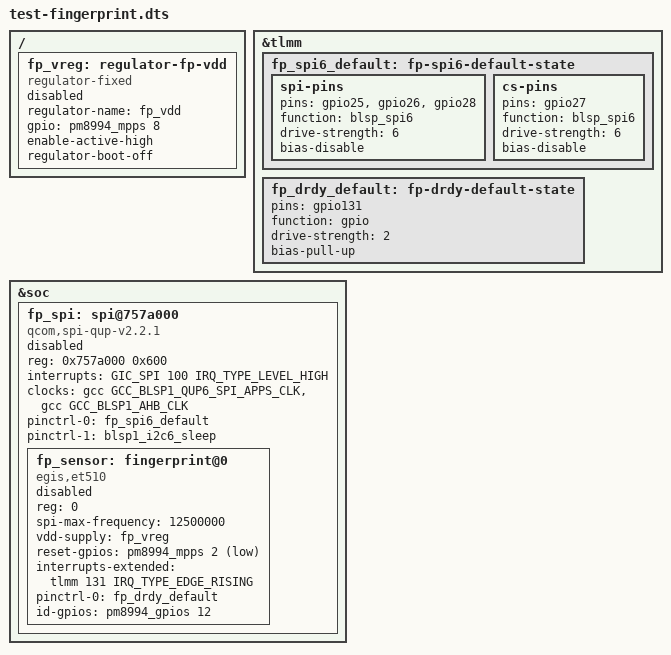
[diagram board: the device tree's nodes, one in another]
// SPDX-License-Identifier: BSD-3-Clause
/*
 * TEST ONLY - fingerprint SPI bring-up for the Galaxy Tab S3.
 *
 * Samsung's TrustZone owns BLSP1 QUP6 and TLMM 25-28 (see docs/fingerprint.md).
 * This overlay describes the fingerprint SPI bus and the Egis ET510 sensor as
 * they would look once that bus belongs to the application processor. It is a
 * reference and bring-up aid, NOT a shipping node - which is why both the
 * controller and the sensor are left status = "disabled".
 *
 * ORDERING HAZARD: the kernel muxes the QUP6 pins when the SPI controller
 * probes, at boot. If TrustZone still owns TLMM 25-28 at that point the
 * firmware resets the tablet about 9 s in. So this node must not be enabled
 * until ownership has been handed to the application processor
 * (tools/blsp-owner, docs/fingerprint.md "Ownership test"). The safe sequence:
 *   1. boot with these nodes disabled (as shipped here);
 *   2. hand QUP6 to APSS at runtime and confirm no reset;
 *   3. only then enable &fp_spi / &fp_sensor (a runtime DT overlay, or a
 *      rebuild with status = "okay"), so the controller probes afterwards.
 *
 * Never send the NVM-write opcodes (0x42/0x46) to the sensor (NVM holds its
 * factory calibration). See docs/fingerprint-protocol.md.
 */

#include "../apq8096-samsung-gts3lwifi.dts"

&tlmm {
	/*
	 * Free TLMM 25-28 so Linux can mux blsp_spi6. Only valid after the
	 * ownership hand-off; see the ordering hazard above. (Wi-Fi model
	 * reserves only 25-28; on the LTE model keep 58-61 reserved.)
	 */
	/delete-property/ gpio-reserved-ranges;

	fp_spi6_default: fp-spi6-default-state {
		spi-pins {
			pins = "gpio25", "gpio26", "gpio28"; /* MOSI, MISO, CLK */
			function = "blsp_spi6";
			drive-strength = <6>;
			bias-disable;
		};

		cs-pins {
			pins = "gpio27"; /* CS_N */
			function = "blsp_spi6";
			drive-strength = <6>;
			bias-disable;
		};
	};

	fp_drdy_default: fp-drdy-default-state {
		pins = "gpio131";
		function = "gpio";
		drive-strength = <2>;
		bias-pull-up;
	};
};

/ {
	/*
	 * BTP_LDO_EN (PM8994 MPP 8) switches the sensor's board LDO. Modelled
	 * as a GPIO-enabled fixed regulator so the sensor driver can sequence
	 * power with vdd-supply.
	 */
	fp_vreg: regulator-fp-vdd {
		compatible = "regulator-fixed";
		regulator-name = "fp_vdd";
		gpio = <&pm8994_mpps 8 GPIO_ACTIVE_HIGH>;
		enable-active-high;
		regulator-boot-off;
		status = "disabled";
	};
};

&soc {
	/*
	 * BLSP1 QUP6 as SPI. Same registers as blsp1_i2c6 in msm8996.dtsi
	 * (0x757a000); PIO only, no dmas (BAM stays off, as in the stock
	 * secure setup). Enable only after the ownership hand-off.
	 */
	fp_spi: spi@757a000 {
		compatible = "qcom,spi-qup-v2.2.1";
		reg = <0x757a000 0x600>;
		interrupts = <GIC_SPI 100 IRQ_TYPE_LEVEL_HIGH>;
		clocks = <&gcc GCC_BLSP1_QUP6_SPI_APPS_CLK>,
			 <&gcc GCC_BLSP1_AHB_CLK>;
		clock-names = "core", "iface";
		pinctrl-names = "default", "sleep";
		pinctrl-0 = <&fp_spi6_default>;
		pinctrl-1 = <&blsp1_i2c6_sleep>;
		#address-cells = <1>;
		#size-cells = <0>;
		status = "disabled";

		fp_sensor: fingerprint@0 {
			compatible = "egis,et510";
			reg = <0>;
			spi-max-frequency = <12500000>;

			vdd-supply = <&fp_vreg>;
			reset-gpios = <&pm8994_mpps 2 GPIO_ACTIVE_LOW>;
			interrupts-extended = <&tlmm 131 IRQ_TYPE_EDGE_RISING>;
			pinctrl-names = "default";
			pinctrl-0 = <&fp_drdy_default>;

			/* BTP_ID (PM8994 GPIO 12) selects the sensor vendor */
			id-gpios = <&pm8994_gpios 12 GPIO_ACTIVE_HIGH>;

			status = "disabled";
		};
	};
};
